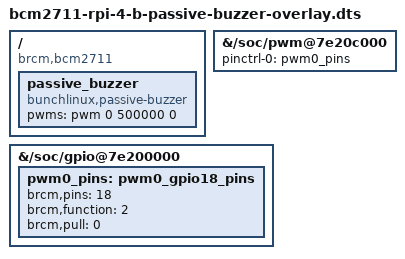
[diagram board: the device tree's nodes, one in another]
/dts-v1/;
/plugin/;

/ {
    compatible = "brcm,bcm2711";

    fragment@0 {
        target-path = "/soc/pwm@7e20c000";
        __overlay__ {
            status = "okay";
            pinctrl-names = "default";
            pinctrl-0 = <&pwm0_pins>;
        };
    };

    fragment@1 {
        target-path = "/soc/gpio@7e200000";
        __overlay__ {
            pwm0_pins: pwm0_gpio18_pins {
                brcm,pins = <18>;
                brcm,function = <2>;  // ALT5 = PWM
                brcm,pull = <0>;
            };
        };
    };

    fragment@2 {
        target-path = "/";
        __overlay__ {
            passive_buzzer {
                compatible = "bunchlinux,passive-buzzer";
                pwms = <&pwm 0 500000 0>;
                status = "okay";
            };
        };
    };
};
